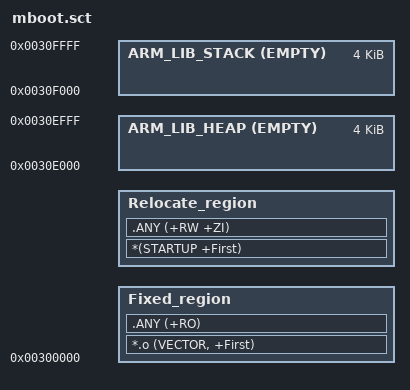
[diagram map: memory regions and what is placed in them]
;------------------------------------------------------------------------------
;
;------------------------------------------------------------------------------

Load_region 0x300000 0x10000 {    

    Fixed_region 0x300000 {
        *.o (VECTOR, +First)
        .ANY (+RO)
    }
    
    Relocate_region +0  {
        *(STARTUP +First)
        .ANY (+RW +ZI)
    }
    
    ScatterAssert((ImageLength(Fixed_region) + ImageLength(Relocate_region)) <  0xF000)
     
    ARM_LIB_HEAP 0x30E000 EMPTY 0x1000 {
    }
    
    ARM_LIB_STACK 0x310000 EMPTY -0x1000 {
    }
}
